# STM32H742AGI6 register map
File version: 1.0
Registers are 32-bit, access not given, reset 0x0 unless marked. A register's access mark holds for its fields unless they carry their own. Offsets are from the block's base; [hi:lo] are bit positions; {n}, {i} and the like mark numbered series; 'fields as' and 'values as' point back to an identical list.

## FMC
Base 0x52004000
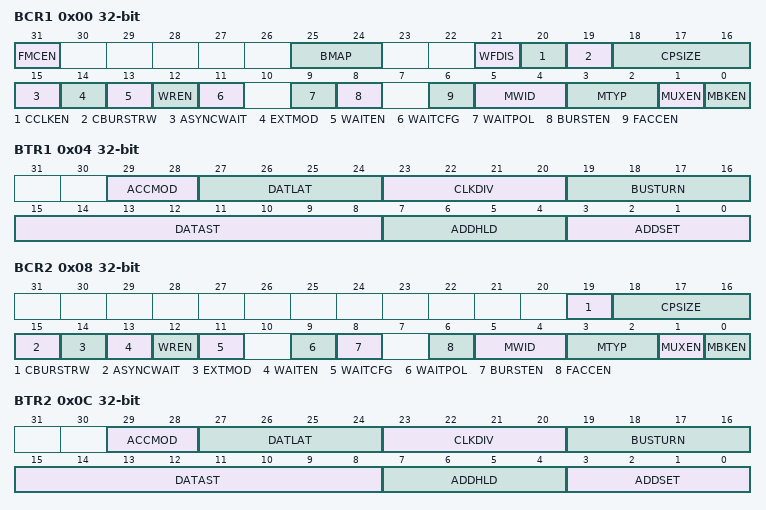
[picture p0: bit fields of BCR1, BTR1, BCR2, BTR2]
0x00 BCR1
  [31] FMCEN, [25:24] BMAP, [21] WFDIS, [20] CCLKEN, [19] CBURSTRW, [18:16] CPSIZE, [15] ASYNCWAIT, [14] EXTMOD, [13] WAITEN, [12] WREN, [11] WAITCFG, [9] WAITPOL, [8] BURSTEN, [6] FACCEN, [5:4] MWID, [3:2] MTYP, [1] MUXEN, [0] MBKEN
0x04 BTR1
  [29:28] ACCMOD, [27:24] DATLAT, [23:20] CLKDIV, [19:16] BUSTURN, [15:8] DATAST, [7:4] ADDHLD, [3:0] ADDSET
0x08 BCR2
  [19] CBURSTRW, [18:16] CPSIZE, [15] ASYNCWAIT, [14] EXTMOD, [13] WAITEN, [12] WREN, [11] WAITCFG, [9] WAITPOL, [8] BURSTEN, [6] FACCEN, [5:4] MWID, [3:2] MTYP, [1] MUXEN, [0] MBKEN
0x0C BTR2
  fields as BTR1
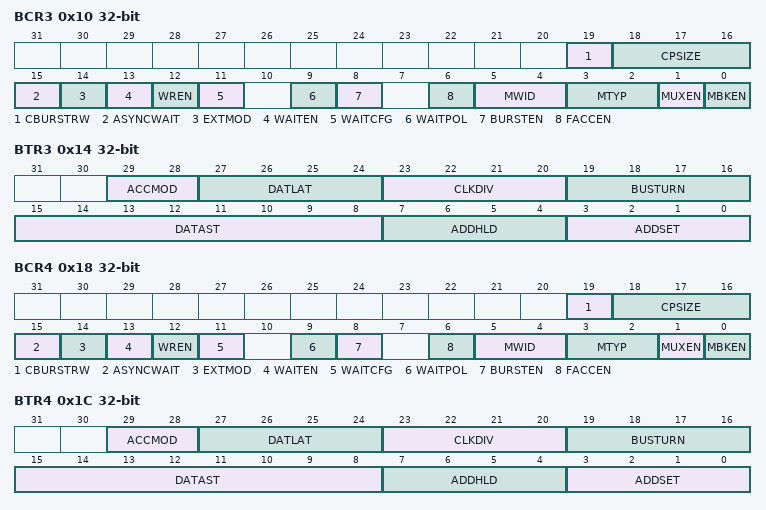
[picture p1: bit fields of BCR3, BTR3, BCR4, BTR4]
0x10 BCR3
  fields as BCR2
0x14 BTR3
  fields as BTR1
0x18 BCR4
  fields as BCR2
0x1C BTR4
  fields as BTR1
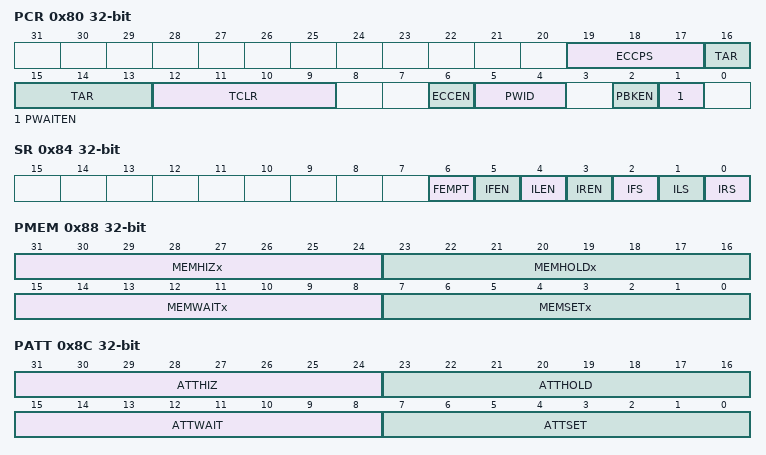
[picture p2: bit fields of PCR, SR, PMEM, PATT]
0x80 PCR
  [19:17] ECCPS, [16:13] TAR, [12:9] TCLR, [6] ECCEN, [5:4] PWID, [2] PBKEN, [1] PWAITEN
0x84 SR
  [6] FEMPT, [5] IFEN, [4] ILEN, [3] IREN, [2] IFS, [1] ILS, [0] IRS
0x88 PMEM
  [31:24] MEMHIZx, [23:16] MEMHOLDx, [15:8] MEMWAITx, [7:0] MEMSETx
0x8C PATT
  [31:24] ATTHIZ, [23:16] ATTHOLD, [15:8] ATTWAIT, [7:0] ATTSET
0x94 ECCR
  [31:0] ECC
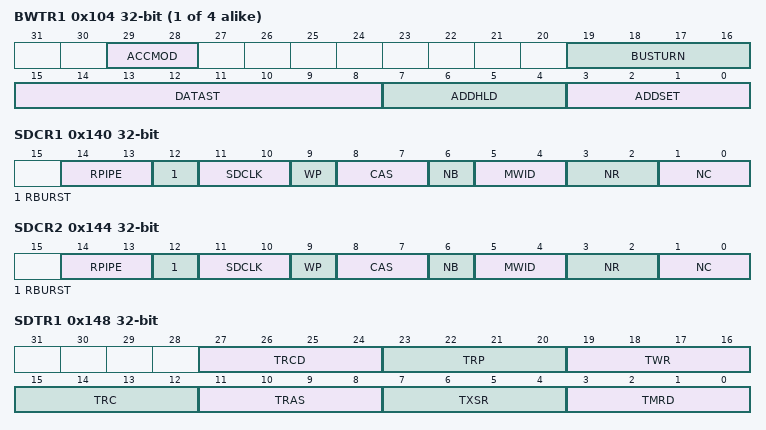
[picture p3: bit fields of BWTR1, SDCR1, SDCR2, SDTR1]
{0xFC+8i} BWTR{i} (i=1..4)
  [29:28] ACCMOD, [19:16] BUSTURN, [15:8] DATAST, [7:4] ADDHLD, [3:0] ADDSET
0x140 SDCR1
  [14:13] RPIPE, [12] RBURST, [11:10] SDCLK, [9] WP, [8:7] CAS, [6] NB, [5:4] MWID, [3:2] NR, [1:0] NC
0x144 SDCR2
  fields as SDCR1
0x148 SDTR1
  [27:24] TRCD, [23:20] TRP, [19:16] TWR, [15:12] TRC, [11:8] TRAS, [7:4] TXSR, [3:0] TMRD
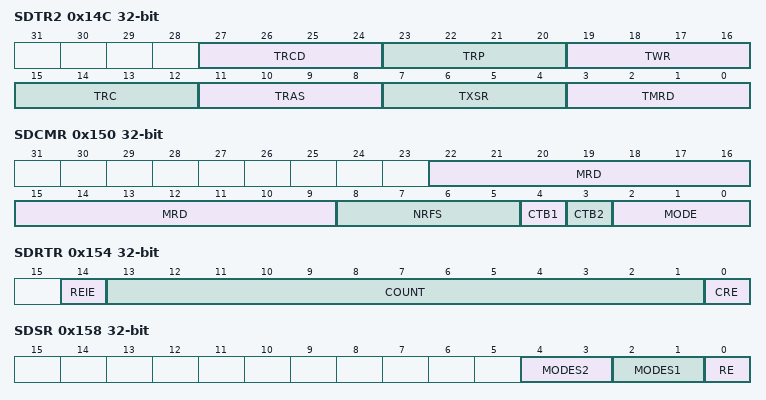
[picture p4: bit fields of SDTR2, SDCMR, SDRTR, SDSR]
0x14C SDTR2
  fields as SDTR1
0x150 SDCMR
  [22:9] MRD, [8:5] NRFS, [4] CTB1, [3] CTB2, [2:0] MODE
0x154 SDRTR
  [14] REIE, [13:1] COUNT, [0] CRE
0x158 SDSR
  [4:3] MODES2, [2:1] MODES1, [0] RE

## QUADSPI
Base 0x52005000
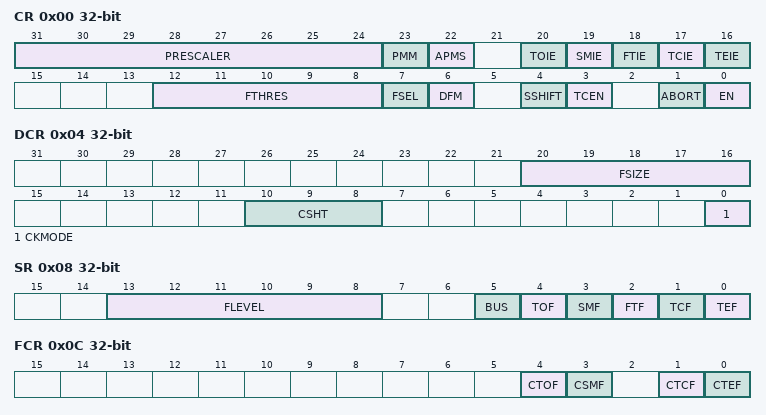
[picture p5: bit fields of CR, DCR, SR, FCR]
0x00 CR
  [31:24] PRESCALER, [23] PMM, [22] APMS, [20] TOIE, [19] SMIE, [18] FTIE, [17] TCIE, [16] TEIE, [12:8] FTHRES, [7] FSEL, [6] DFM, [4] SSHIFT, [3] TCEN, [1] ABORT, [0] EN
0x04 DCR
  [20:16] FSIZE, [10:8] CSHT, [0] CKMODE
0x08 SR
  [13:8] FLEVEL, [5] BUS, [4] TOF, [3] SMF, [2] FTF, [1] TCF, [0] TEF
0x0C FCR
  [4] CTOF, [3] CSMF, [1] CTCF, [0] CTEF
0x10 DLR
  [31:0] DL
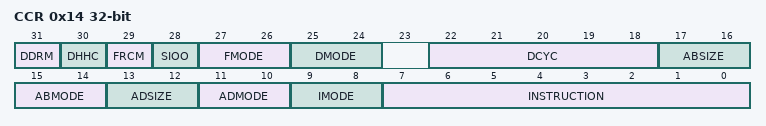
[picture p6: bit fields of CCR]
0x14 CCR
  [31] DDRM, [30] DHHC, [29] FRCM, [28] SIOO, [27:26] FMODE, [25:24] DMODE, [22:18] DCYC, [17:16] ABSIZE, [15:14] ABMODE, [13:12] ADSIZE, [11:10] ADMODE, [9:8] IMODE, [7:0] INSTRUCTION
0x18 AR
  [31:0] ADDRESS
0x1C ABR
  [31:0] ALTERNATE
0x20 DR
  [31:0] DATA
0x24 PSMKR
  [31:0] MASK
0x28 PSMAR
  [31:0] MATCH
0x2C PIR
  [15:0] INTERVAL
0x30 LPTR
  [15:0] TIMEOUT

## EXTI
Base 0x58000000
0x00 RTSR1
  [21:0] TR
0x04 FTSR1
  [21:0] TR
0x08 SWIER1
  [21:0] SWIER
0x0C D3PMR1
  [25:0] MR
0x10 D3PCR1L
  [31:0] PCS
0x14 D3PCR1H
  [19:6] PCS
0x20 RTSR2
  [19:17] TR
0x24 FTSR2
  [19:17] TR
0x28 SWIER2
  [19:17] SWIER
0x2C D3PMR2
  [21:2] MR
0x30 D3PCR2L
  [19:4] PCS
0x34 D3PCR2H
  [11:0] PCS
0x40 RTSR3
  [22:18] TR
0x44 FTSR3
  [22:18] TR
0x48 SWIER3
  [22:18] SWIER
0x4C D3PMR3
  [24] MR
0x50 D3PCR3L
0x54 D3PCR3H
  [17:16] PCS
0x80 CPUIMR1
  [31:0] MR
0x84 CPUEMR1
  [31:0] MR
0x88 CPUPR1
  [21:0] PR
0x90 CPUIMR2
  [31:0] MR
0x94 CPUEMR2
  [31:0] MR
0x98 CPUPR2
  [19:17] PR
0xA0 CPUIMR3
  [24:0] MR
0xA4 CPUEMR3
  [24:0] MR
0xA8 CPUPR3
  [22:18] PR

## SYSCFG
Base 0x58000400
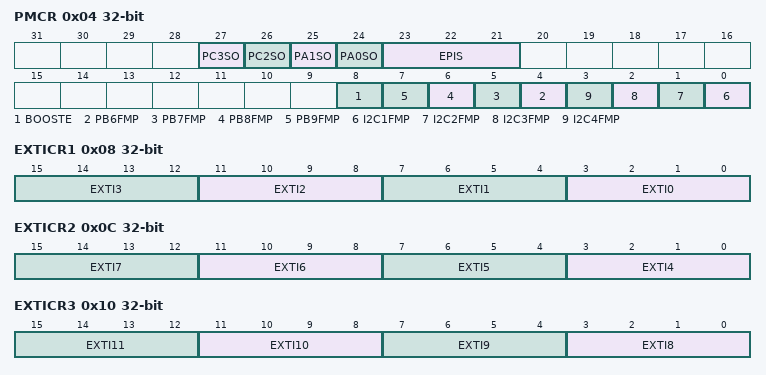
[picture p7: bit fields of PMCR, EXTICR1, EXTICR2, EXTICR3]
0x04 PMCR
  [27] PC3SO, [26] PC2SO, [25] PA1SO, [24] PA0SO, [23:21] EPIS, [8] BOOSTE, [n-2] PB{n}FMP (n=6..9), [n-1] I2C{n}FMP (n=1..4)
0x08 EXTICR1
  [4n+3:4n] EXTI{n} (n=0..3)
0x0C EXTICR2
  [4n-13:4n-16] EXTI{n} (n=4..7)
0x10 EXTICR3
  [4n-29:4n-32] EXTI{n} (n=8..11)
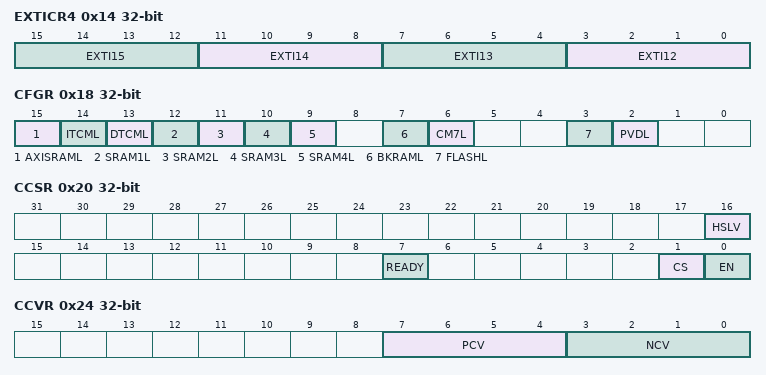
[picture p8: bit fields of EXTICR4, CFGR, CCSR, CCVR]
0x14 EXTICR4
  [4n-45:4n-48] EXTI{n} (n=12..15)
0x18 CFGR
  [15] AXISRAML, [14] ITCML, [13] DTCML, [13-n] SRAM{n}L (n=1..4), [7] BKRAML, [6] CM7L, [3] FLASHL, [2] PVDL
0x20 CCSR
  [16] HSLV, [7] READY, [1] CS, [0] EN
0x24 CCVR
  [7:4] PCV, [3:0] NCV
0x2C CCCR
  [0] ODEN
0x124 PKGR
  [3:0] PKG
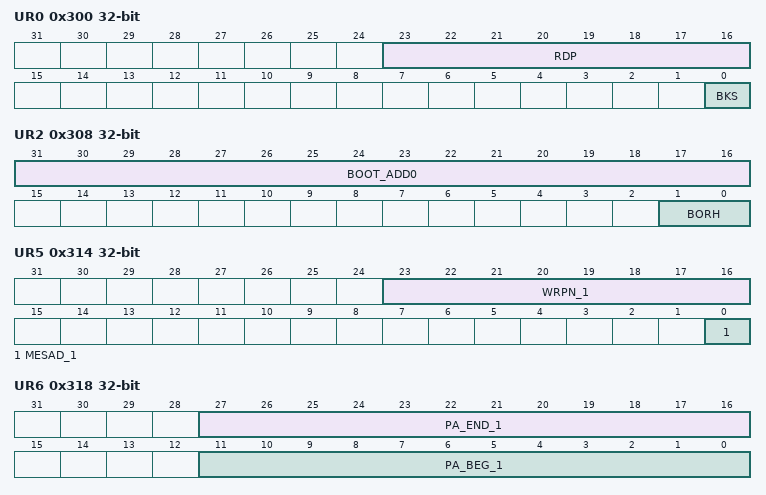
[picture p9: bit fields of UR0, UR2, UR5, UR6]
0x300 UR0
  [23:16] RDP, [0] BKS
0x308 UR2
  [31:16] BOOT_ADD0, [1:0] BORH
0x30C UR3
  [15:0] BOOT_ADD1
0x310 UR4
  [16] MEPAD_1
0x314 UR5
  [23:16] WRPN_1, [0] MESAD_1
0x318 UR6
  [27:16] PA_END_1, [11:0] PA_BEG_1
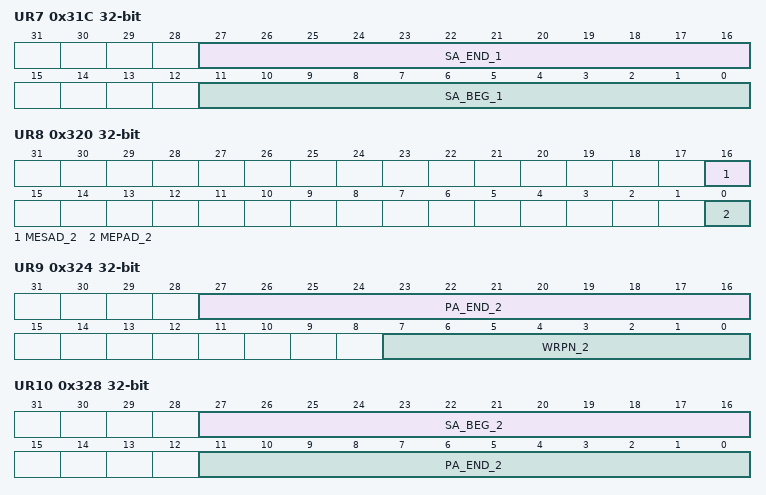
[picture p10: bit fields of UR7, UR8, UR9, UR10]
0x31C UR7
  [27:16] SA_END_1, [11:0] SA_BEG_1
0x320 UR8
  [16] MESAD_2, [0] MEPAD_2
0x324 UR9
  [27:16] PA_END_2, [7:0] WRPN_2
0x328 UR10
  [27:16] SA_BEG_2, [11:0] PA_END_2
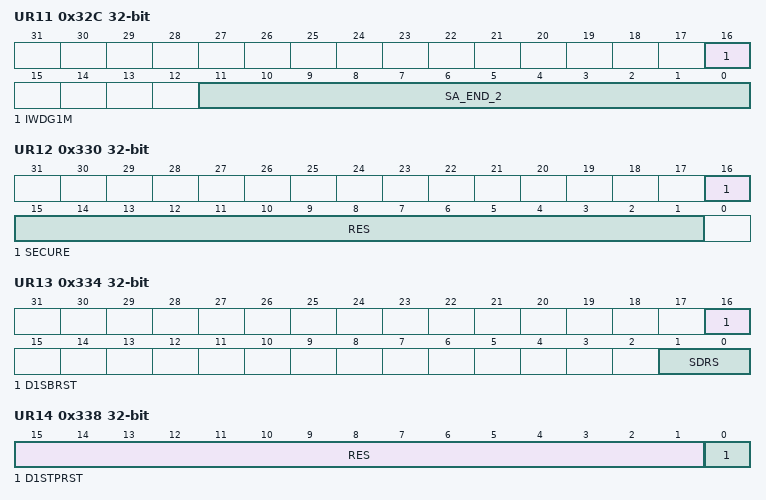
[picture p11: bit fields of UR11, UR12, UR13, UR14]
0x32C UR11
  [16] IWDG1M, [11:0] SA_END_2
0x330 UR12
  [16] SECURE, [15:1] RES
0x334 UR13
  [16] D1SBRST, [1:0] SDRS
0x338 UR14
  [15:1] RES, [0] D1STPRST
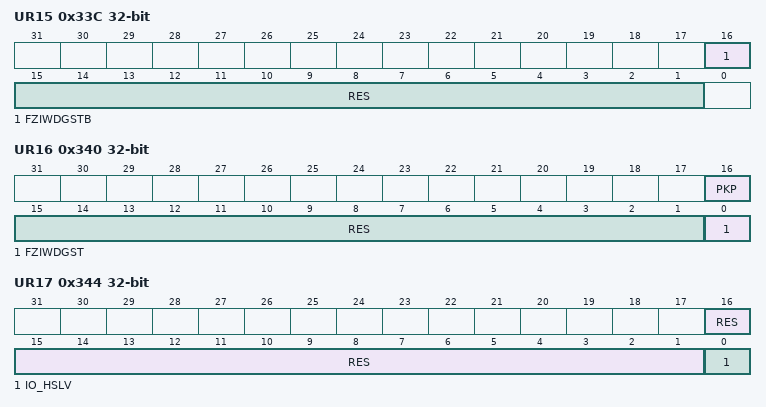
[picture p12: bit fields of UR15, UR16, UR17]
0x33C UR15
  [16] FZIWDGSTB, [15:1] RES
0x340 UR16
  [16] PKP, [15:1] RES, [0] FZIWDGST
0x344 UR17
  [16:1] RES, [0] IO_HSLV
